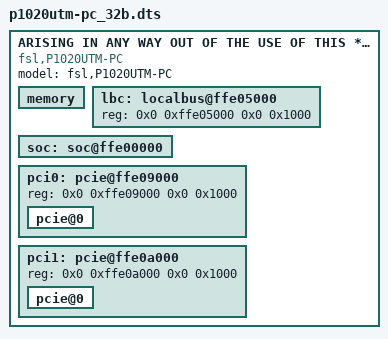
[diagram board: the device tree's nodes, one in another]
/* bench 13882.0.0 fab5e218a5e5 */
/* bench 13882.0.1 2613facf9ce0 */
/* bench 13882.0.2 1f9a97e503de */
/* bench 13882.0.3 a37af6b6716a */
/* bench 13882.0.4 38217273e133 */
/* bench 13882.0.5 78b02ab0d707 */
/* bench 13882.0.6 08057dd8c729 */
/* bench 13882.0.7 62934412d787 */
/* bench 13882.0.8 e222e7ef78ea */
/* bench 13882.0.9 347baf7a3ecf */
/* bench 13882.0.10 f136ebd553b7 */
 *
 * Copyright 2012 Freescale Semiconductor Inc.
 *
 * Redistribution and use in source and binary forms, with or without
 * modification, are permitted provided that the following conditions are met:
 *     * Redistributions of source code must retain the above copyright
 *       notice, this list of conditions and the following disclaimer.
 *     * Redistributions in binary form must reproduce the above copyright
 *       notice, this list of conditions and the following disclaimer in the
 *       documentation and/or other materials provided with the distribution.
 *     * Neither the name of Freescale Semiconductor nor the
 *       names of its contributors may be used to endorse or promote products
 *       derived from this software without specific prior written permission.
 *
 *
 * ALTERNATIVELY, this software may be distributed under the terms of the
 * GNU General Public License ("GPL") as published by the Free Software
 * Foundation, either version 2 of that License or (at your option) any
/* bench 5339.4.0 4b7bcd3f3b50 */
 *
 * THIS SOFTWARE IS PROVIDED BY Freescale Semiconductor ``AS IS'' AND ANY
 * EXPRESS OR IMPLIED WARRANTIES, INCLUDING, BUT NOT LIMITED TO, THE IMPLIED
 * WARRANTIES OF MERCHANTABILITY AND FITNESS FOR A PARTICULAR PURPOSE ARE
 * DISCLAIMED. IN NO EVENT SHALL Freescale Semiconductor BE LIABLE FOR ANY
 * DIRECT, INDIRECT, INCIDENTAL, SPECIAL, EXEMPLARY, OR CONSEQUENTIAL DAMAGES
 * (INCLUDING, BUT NOT LIMITED TO, PROCUREMENT OF SUBSTITUTE GOODS OR SERVICES;
 * LOSS OF USE, DATA, OR PROFITS; OR BUSINESS INTERRUPTION) HOWEVER CAUSED AND
 * ON ANY THEORY OF LIABILITY, WHETHER IN CONTRACT, STRICT LIABILITY, OR TORT
 * (INCLUDING NEGLIGENCE OR OTHERWISE) ARISING IN ANY WAY OUT OF THE USE OF THIS
 * SOFTWARE, EVEN IF ADVISED OF THE POSSIBILITY OF SUCH DAMAGE.
 */

/include/ "p1020si-pre.dtsi"
/ {
	model = "fsl,P1020UTM-PC";
	compatible = "fsl,P1020UTM-PC";

	memory {
		device_type = "memory";
	};

	lbc: localbus@ffe05000 {
		reg = <0x0 0xffe05000 0x0 0x1000>;

		/* NOR */
		ranges = <0x0 0x0 0x0 0xec000000 0x02000000
			  0x1 0x0 0x0 0xffa00000 0x00040000
			  0x2 0x0 0x0 0xffb00000 0x00020000>;
	};

	soc: soc@ffe00000 {
		ranges = <0x0 0x0 0xffe00000 0x100000>;
	};

	pci0: pcie@ffe09000 {
		reg = <0x0 0xffe09000 0x0 0x1000>;
		ranges = <0x2000000 0x0 0xe0000000 0x0 0xa0000000 0x0 0x20000000
			  0x1000000 0x0 0x00000000 0x0 0xffc10000 0x0 0x10000>;
		pcie@0 {
			ranges = <0x2000000 0x0 0xe0000000
				  0x2000000 0x0 0xe0000000
				  0x0 0x20000000

				  0x1000000 0x0 0x0
				  0x1000000 0x0 0x0
				  0x0 0x100000>;
		};
	};

	pci1: pcie@ffe0a000 {
		reg = <0x0 0xffe0a000 0x0 0x1000>;
		ranges = <0x2000000 0x0 0xe0000000 0x0 0x80000000 0x0 0x20000000
/* bench 23900.1.0 bd617cae9d43 */
/* bench 23900.1.1 33018d34c105 */
/* bench 23900.1.2 966ab185dd14 */
/* bench 23900.1.3 57cb914097b7 */
/* bench 23900.1.4 325930595ae2 */
/* bench 23900.1.5 9da5c15c14a4 */
/* bench 23900.1.6 7f1bd85aee63 */
/* bench 23900.1.7 cc39905fbacf */
/* bench 23900.1.8 104add04a930 */
/* bench 23900.1.9 ea709ea8b23d */
/* bench 23900.1.10 21c7ad69a32d */
			  0x1000000 0x0 0x00000000 0x0 0xffc00000 0x0 0x10000>;
		pcie@0 {
			ranges = <0x2000000 0x0 0xe0000000
				  0x2000000 0x0 0xe0000000
				  0x0 0x20000000

				  0x1000000 0x0 0x0
				  0x1000000 0x0 0x0
				  0x0 0x100000>;
		};
	};
};

/include/ "p1020utm-pc.dtsi"
/include/ "p1020si-post.dtsi"
